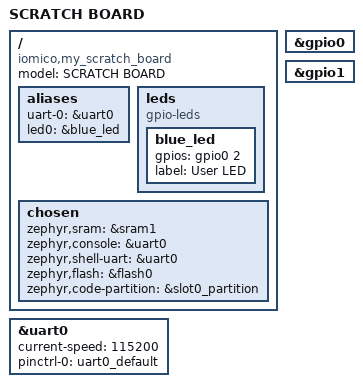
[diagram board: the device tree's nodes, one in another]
/dts-v1/;

#include <espressif/esp32/esp32_wroom_32ue_n4.dtsi>
#include "doit_esp32_devkit_v1-pinctrl.dtsi"
#include <zephyr/dt-bindings/input/input-event-codes.h>
#include <zephyr/dt-bindings/input/esp32-touch-sensor-input.h>
#include <espressif/partitions_0x1000_amp.dtsi>

/ {
	model = "SCRATCH BOARD";
	compatible = "iomico,my_scratch_board";

	aliases {
		uart-0 = &uart0;
		led0 = &blue_led;
	};

	leds {
		compatible = "gpio-leds";

		blue_led: blue_led {
			gpios = <&gpio0 2 GPIO_ACTIVE_HIGH>;
			label = "User LED";
		};
	};


	chosen {
		zephyr,sram = &sram1;
		zephyr,console = &uart0;
		zephyr,shell-uart = &uart0;
		zephyr,flash = &flash0;
		zephyr,code-partition = &slot0_partition;
	};
};

&uart0 {
	status = "okay";
	current-speed = <115200>;
	pinctrl-0 = <&uart0_default>;
	pinctrl-names = "default";
};

&gpio0 {
	status = "okay";
};

&gpio1 {
	status = "okay";
};




